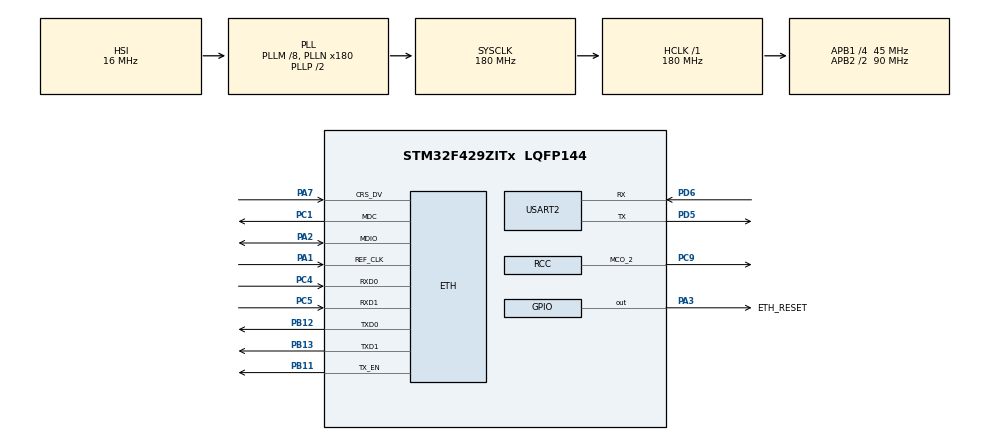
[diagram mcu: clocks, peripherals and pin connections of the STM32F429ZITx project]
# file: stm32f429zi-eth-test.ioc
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ETH.MediaInterface=ETH_MEDIA_INTERFACE_RMII
Mcu.Family=STM32F4
Mcu.Name=STM32F429ZITx
Mcu.Package=LQFP144
NVIC.PriorityGroup=NVIC_PRIORITYGROUP_4
PA1.Mode=RMII
PA1.Signal=ETH_REF_CLK
PA13.Mode=Serial_Wire
PA13.Signal=SYS_JTMS-SWDIO
PA14.Mode=Serial_Wire
PA14.Signal=SYS_JTCK-SWCLK
PA2.Mode=RMII
PA2.Signal=ETH_MDIO
PA3.GPIO_Label=ETH_RESET
PA3.PinState=GPIO_PIN_SET
PA3.Signal=GPIO_Output
PA7.Mode=RMII
PA7.Signal=ETH_CRS_DV
PB11.Mode=RMII
PB11.Signal=ETH_TX_EN
PB12.Mode=RMII
PB12.Signal=ETH_TXD0
PB13.Mode=RMII
PB13.Signal=ETH_TXD1
PC1.Mode=RMII
PC1.Signal=ETH_MDC
PC4.Mode=RMII
PC4.Signal=ETH_RXD0
PC5.Mode=RMII
PC5.Signal=ETH_RXD1
PC9.Mode=Clock-out-2
PC9.Signal=RCC_MCO_2
PD5.Mode=Asynchronous
PD5.Signal=USART2_TX
PD6.Mode=Asynchronous
PD6.Signal=USART2_RX
PH0/OSC_IN.Mode=HSE-External-Clock-Source
PH0/OSC_IN.Signal=RCC_OSC_IN
PH1/OSC_OUT.Mode=HSE-External-Clock-Source
PH1/OSC_OUT.Signal=RCC_OSC_OUT
ProjectManager.HeapSize=0x2000
ProjectManager.StackSize=0x4000
ProjectManager.TargetToolchain=Makefile
RCC.48MHZClocksFreq_Value=90000000
RCC.AHBFreq_Value=180000000
RCC.APB1CLKDivider=RCC_HCLK_DIV4
RCC.APB1Freq_Value=45000000
RCC.APB1TimFreq_Value=90000000
RCC.APB2CLKDivider=RCC_HCLK_DIV2
RCC.APB2Freq_Value=90000000
RCC.APB2TimFreq_Value=180000000
RCC.CortexFreq_Value=180000000
RCC.HCLKFreq_Value=180000000
RCC.HSE_VALUE=25000000
RCC.HSI_VALUE=16000000
RCC.LSE_VALUE=32768
RCC.PLLM=8
RCC.PLLN=180
RCC.RCC_MCO2Source=RCC_MCO2SOURCE_PLLI2SCLK
RCC.RCC_MCODiv2=RCC_MCODIV_4
RCC.SYSCLKFreq_VALUE=180000000
RCC.SYSCLKSource=RCC_SYSCLKSOURCE_PLLCLK
RCC.VCOOutputFreq_Value=360000000
USART2.VirtualMode=VM_ASYNC
board=custom

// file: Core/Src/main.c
/* USER CODE BEGIN Header */
/**
  ******************************************************************************
  * @file           : main.c
  * @brief          : Main program body
  ******************************************************************************
  * @attention
  *
  * <h2><center>&copy; Copyright (c) 2022 STMicroelectronics.
  * All rights reserved.</center></h2>
  *
  * This software component is licensed by ST under BSD 3-Clause license,
  * the "License"; You may not use this file except in compliance with the
  * License. You may obtain a copy of the License at:
  *                        opensource.org/licenses/BSD-3-Clause
  *
  ******************************************************************************
  */
/* USER CODE END Header */
#include "main.h"
#include "eth.h"
#include "usart.h"
#include "gpio.h"

/* USER CODE BEGIN Includes */
#include <stdio.h>
#include "retarget.h"
/* USER CODE END Includes */

void SystemClock_Config(void);

/* USER CODE BEGIN 0 */
int fputc(int ch, FILE *f)
{
  if (HAL_UART_Transmit(&huart2, &ch, 1, HAL_MAX_DELAY) != HAL_OK)
      Error_Handler();
  return ch;
}
/* USER CODE END 0 */

int main(void)
{

  /* MCU Configuration--------------------------------------------------------*/

  /* Reset of all peripherals, Initializes the Flash interface and the Systick. */
  HAL_Init();

  /* Configure the system clock */
  SystemClock_Config();

  /* Initialize all configured peripherals */
  MX_GPIO_Init();
  MX_USART2_UART_Init();
  MX_ETH_Init();
  /* USER CODE BEGIN 2 */
  RetargetInit(&huart2);

  printf("ETH Test Start\n");
  /* USER CODE END 2 */

  /* Infinite loop */
  /* USER CODE BEGIN WHILE */

  while (1)
  {
    if (HAL_ETH_GetReceivedFrame(&heth) != HAL_OK)
      printf("ERROR\n");
    /* USER CODE END WHILE */

    /* USER CODE BEGIN 3 */
    HAL_Delay(500);
  }
  /* USER CODE END 3 */
}

void SystemClock_Config(void)
{
  RCC_OscInitTypeDef RCC_OscInitStruct = {0};
  RCC_ClkInitTypeDef RCC_ClkInitStruct = {0};
  RCC_PeriphCLKInitTypeDef PeriphClkInitStruct = {0};

  /** Configure the main internal regulator output voltage
  */
  __HAL_RCC_PWR_CLK_ENABLE();
  __HAL_PWR_VOLTAGESCALING_CONFIG(PWR_REGULATOR_VOLTAGE_SCALE1);
  /** Initializes the RCC Oscillators according to the specified parameters
  * in the RCC_OscInitTypeDef structure.
  */
  RCC_OscInitStruct.OscillatorType = RCC_OSCILLATORTYPE_HSI;
  RCC_OscInitStruct.HSIState = RCC_HSI_ON;
  RCC_OscInitStruct.HSICalibrationValue = RCC_HSICALIBRATION_DEFAULT;
  RCC_OscInitStruct.PLL.PLLState = RCC_PLL_ON;
  RCC_OscInitStruct.PLL.PLLSource = RCC_PLLSOURCE_HSI;
  RCC_OscInitStruct.PLL.PLLM = 8;
  RCC_OscInitStruct.PLL.PLLN = 180;
  RCC_OscInitStruct.PLL.PLLP = RCC_PLLP_DIV2;
  RCC_OscInitStruct.PLL.PLLQ = 4;
  if (HAL_RCC_OscConfig(&RCC_OscInitStruct) != HAL_OK)
  {
    Error_Handler();
  }
  /** Activate the Over-Drive mode
  */
  if (HAL_PWREx_EnableOverDrive() != HAL_OK)
  {
    Error_Handler();
  }
  /** Initializes the CPU, AHB and APB buses clocks
  */
  RCC_ClkInitStruct.ClockType = RCC_CLOCKTYPE_HCLK|RCC_CLOCKTYPE_SYSCLK
                              |RCC_CLOCKTYPE_PCLK1|RCC_CLOCKTYPE_PCLK2;
  RCC_ClkInitStruct.SYSCLKSource = RCC_SYSCLKSOURCE_PLLCLK;
  RCC_ClkInitStruct.AHBCLKDivider = RCC_SYSCLK_DIV1;
  RCC_ClkInitStruct.APB1CLKDivider = RCC_HCLK_DIV4;
  RCC_ClkInitStruct.APB2CLKDivider = RCC_HCLK_DIV2;

  if (HAL_RCC_ClockConfig(&RCC_ClkInitStruct, FLASH_LATENCY_5) != HAL_OK)
  {
    Error_Handler();
  }
  PeriphClkInitStruct.PeriphClockSelection = RCC_PERIPHCLK_PLLI2S;
  PeriphClkInitStruct.PLLI2S.PLLI2SN = 192;
  PeriphClkInitStruct.PLLI2S.PLLI2SR = 2;
  PeriphClkInitStruct.PLLI2S.PLLI2SQ = 2;
  if (HAL_RCCEx_PeriphCLKConfig(&PeriphClkInitStruct) != HAL_OK)
  {
    Error_Handler();
  }
  HAL_RCC_MCOConfig(RCC_MCO2, RCC_MCO2SOURCE_PLLI2SCLK, RCC_MCODIV_4);
}

void Error_Handler(void)
{
  __disable_irq();
  while (1)
  {
  }
}

/************************ (C) COPYRIGHT STMicroelectronics *****END OF FILE****/
